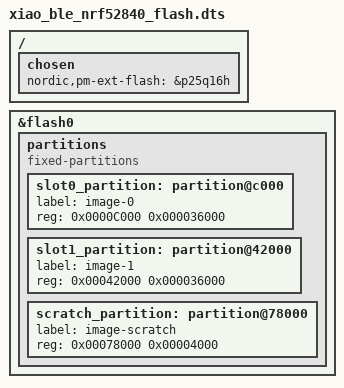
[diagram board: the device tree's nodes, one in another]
/dts-v1/;

// Might need to change this to the correct path
#include <../../boards/seeed/xiao_ble/xiao_ble.dts>

/ {
	chosen {
		nordic,pm-ext-flash = &p25q16h;
	};
};

&flash0 {
	partitions {
		compatible = "fixed-partitions";
		#address-cells = <1>;
		#size-cells = <1>;

		slot0_partition: partition@c000 {
			label = "image-0";
			reg = <0x0000C000 0x000036000>;
		};
		slot1_partition: partition@42000 {
			label = "image-1";
			reg = <0x00042000 0x000036000>;
		};
		scratch_partition: partition@78000 {
			label = "image-scratch";
			reg = <0x00078000 0x00004000>;
		};
	};
};
